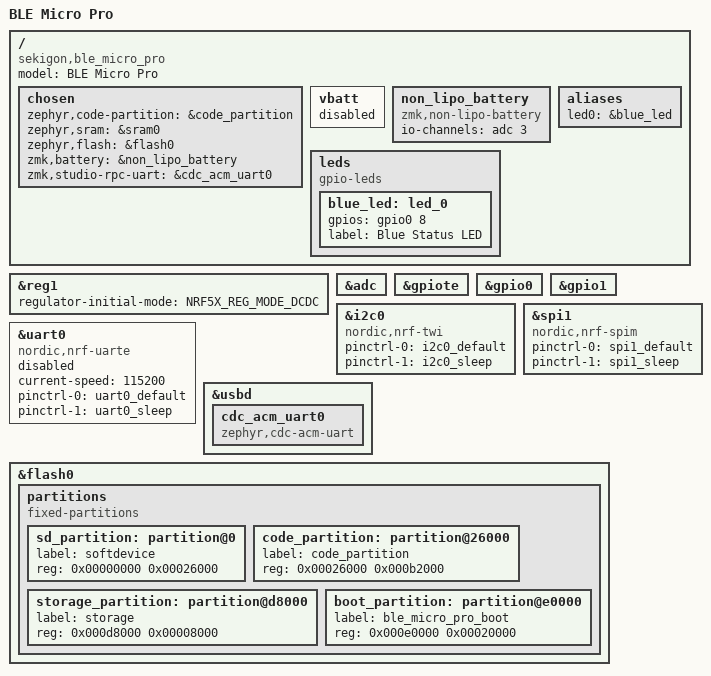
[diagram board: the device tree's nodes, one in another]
/*
 * Copyright (c) 2024 The ZMK Contributors
 * SPDX-License-Identifier: MIT
 */

/dts-v1/;
#include <nordic/nrf52840_qiaa.dtsi>
#include "ble_micro_pro-pinctrl.dtsi"
#include "arduino_pro_micro_pins.dtsi"

/ {
	model = "BLE Micro Pro";
	compatible = "sekigon,ble_micro_pro";

	chosen {
		zephyr,code-partition = &code_partition;
		zephyr,sram = &sram0;
		zephyr,flash = &flash0;
		zmk,battery = &non_lipo_battery;
		zmk,studio-rpc-uart = &cdc_acm_uart0;
	};

	vbatt: vbatt {
		status = "disabled";
	};

	non_lipo_battery: non_lipo_battery {
		compatible = "zmk,non-lipo-battery";
		io-channels = <&adc 3>;
	};

	aliases {
		led0 = &blue_led;
	};

	leds {
		compatible = "gpio-leds";
		blue_led: led_0 {
			gpios = <&gpio0 8 GPIO_ACTIVE_HIGH>;
			label = "Blue Status LED";
		};
	};
};

&reg1 {
	regulator-initial-mode = <NRF5X_REG_MODE_DCDC>;
};

&adc {
	status = "okay";
};

&gpiote {
	status = "okay";
};

&gpio0 {
	status = "okay";
};

&gpio1 {
	status = "okay";
};

&i2c0 {
    compatible = "nordic,nrf-twi";
    status = "okay";
    pinctrl-0 = <&i2c0_default>;
    pinctrl-1 = <&i2c0_sleep>;
    pinctrl-names = "default", "sleep";
};

&spi1 {
    compatible = "nordic,nrf-spim";
    status = "okay";
    pinctrl-0 = <&spi1_default>;
    pinctrl-1 = <&spi1_sleep>;
    pinctrl-names = "default", "sleep";
};

&uart0 {
    compatible = "nordic,nrf-uarte";
    status = "disabled";
    current-speed = <115200>;
    pinctrl-0 = <&uart0_default>;
    pinctrl-1 = <&uart0_sleep>;
    pinctrl-names = "default", "sleep";
};

zephyr_udc0: &usbd {
    status = "okay";
    cdc_acm_uart0: cdc_acm_uart0 {
        compatible = "zephyr,cdc-acm-uart";
    };
};

&flash0 {
	partitions {
		compatible = "fixed-partitions";
		#address-cells = <1>;
		#size-cells = <1>;

		sd_partition: partition@0 {
			label = "softdevice";
			reg = <0x00000000 0x00026000>;
		};
		code_partition: partition@26000 {
			label = "code_partition";
			reg = <0x00026000 0x000b2000>;
		};
		storage_partition: partition@d8000 {
			label = "storage";
			reg = <0x000d8000 0x00008000>;
		};
		boot_partition: partition@e0000 {
			label = "ble_micro_pro_boot";
			reg = <0x000e0000 0x00020000>;
		};
	};
};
